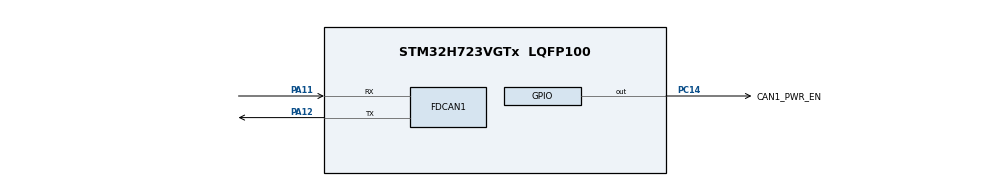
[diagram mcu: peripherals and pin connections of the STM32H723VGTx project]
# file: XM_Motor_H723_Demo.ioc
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FDCAN1.CalculateBaudRateNominal=1000000
FDCAN1.CalculateTimeBitNominal=1000
FDCAN1.CalculateTimeQuantumNominal=200.0
FDCAN1.NominalPrescaler=24
Mcu.Family=STM32H7
Mcu.Name=STM32H723VGTx
Mcu.Package=LQFP100
NVIC.FDCAN1_IT0_IRQn=true\:0\:0\:false\:false\:true\:true\:true\:true
NVIC.PriorityGroup=NVIC_PRIORITYGROUP_4
PA11.Mode=FDCAN_Activate
PA11.Signal=FDCAN1_RX
PA12.Mode=FDCAN_Activate
PA12.Signal=FDCAN1_TX
PC14-OSC32_IN.GPIO_Label=CAN1_PWR_EN
PC14-OSC32_IN.Signal=GPIO_Output
ProjectManager.HeapSize=0x200
ProjectManager.StackSize=0x400
ProjectManager.TargetToolchain=MDK-ARM V5.32
RCC.ADCFreq_Value=129000000
RCC.APB1Freq_Value=120000000
RCC.APB2Freq_Value=120000000
RCC.APB3Freq_Value=120000000
RCC.APB4Freq_Value=120000000
RCC.CortexFreq_Value=480000000
RCC.D1PPRE=RCC_APB3_DIV2
RCC.D2PPRE1=RCC_APB1_DIV2
RCC.D2PPRE2=RCC_APB2_DIV2
RCC.D3PPRE=RCC_APB4_DIV2
RCC.DIVM1=4
RCC.DIVN1=30
RCC.DIVP1=1
RCC.DIVQ1=4
RCC.HCLKFreq_Value=240000000
RCC.HPRE=RCC_HCLK_DIV2
RCC.PLL2FRACN=0
RCC.PLL3FRACN=0
RCC.PLLFRACN=0
RCC.SYSCLKFreq_VALUE=480000000
RCC.SYSCLKSource=RCC_SYSCLKSOURCE_PLLCLK
RCC.USBFreq_Value=120000000
VP_MEMORYMAP_VS_MEMORYMAP.Mode=CurAppReg
board=custom

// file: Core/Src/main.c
/* USER CODE BEGIN Header */
/**
  ******************************************************************************
  * @file           : main.c
  * @brief          : Main program body
  ******************************************************************************
  * @attention
  *
  * Copyright (c) 2024 STMicroelectronics.
  * All rights reserved.
  *
  * This software is licensed under terms that can be found in the LICENSE file
  * in the root directory of this software component.
  * If no LICENSE file comes with this software, it is provided AS-IS.
  *
  ******************************************************************************
  */
/* USER CODE END Header */
#include "main.h"
#include "fdcan.h"
#include "memorymap.h"
#include "gpio.h"

/* USER CODE BEGIN Includes */
#include "MI_motor_dev.h"
/* USER CODE END Includes */

void SystemClock_Config(void);

int main(void)
{

  /* MCU Configuration--------------------------------------------------------*/

  /* Reset of all peripherals, Initializes the Flash interface and the Systick. */
  HAL_Init();

  /* Configure the system clock */
  SystemClock_Config();

  /* Initialize all configured peripherals */
  MX_GPIO_Init();
  MX_FDCAN1_Init();
  /* USER CODE BEGIN 2 */
	HAL_GPIO_WritePin(CAN1_PWR_EN_GPIO_Port,CAN1_PWR_EN_Pin,1);
	MI_Motor_t hmotor;
	MI_motor_init(&hmotor,&hfdcan1);
	MI_motor_get_ID(&hmotor);
	MI_motor_enable(&hmotor,hmotor.EXT_ID.motor_id);
	MI_motor_controlmode(&hmotor, 0.05, 0,0,0,0);
	HAL_Delay(5000);
	MI_motor_stop(&hmotor);
  /* USER CODE END 2 */

  /* Infinite loop */
  while (1)
  {

  }
}

void SystemClock_Config(void)
{
  RCC_OscInitTypeDef RCC_OscInitStruct = {0};
  RCC_ClkInitTypeDef RCC_ClkInitStruct = {0};

  /** Supply configuration update enable
  */
  HAL_PWREx_ConfigSupply(PWR_LDO_SUPPLY);

  /** Configure the main internal regulator output voltage
  */
  __HAL_PWR_VOLTAGESCALING_CONFIG(PWR_REGULATOR_VOLTAGE_SCALE0);

  while(!__HAL_PWR_GET_FLAG(PWR_FLAG_VOSRDY)) {}

  /** Initializes the RCC Oscillators according to the specified parameters
  * in the RCC_OscInitTypeDef structure.
  */
  RCC_OscInitStruct.OscillatorType = RCC_OSCILLATORTYPE_HSI;
  RCC_OscInitStruct.HSIState = RCC_HSI_DIV1;
  RCC_OscInitStruct.HSICalibrationValue = 64;
  RCC_OscInitStruct.PLL.PLLState = RCC_PLL_ON;
  RCC_OscInitStruct.PLL.PLLSource = RCC_PLLSOURCE_HSI;
  RCC_OscInitStruct.PLL.PLLM = 4;
  RCC_OscInitStruct.PLL.PLLN = 30;
  RCC_OscInitStruct.PLL.PLLP = 1;
  RCC_OscInitStruct.PLL.PLLQ = 4;
  RCC_OscInitStruct.PLL.PLLR = 2;
  RCC_OscInitStruct.PLL.PLLRGE = RCC_PLL1VCIRANGE_3;
  RCC_OscInitStruct.PLL.PLLVCOSEL = RCC_PLL1VCOWIDE;
  RCC_OscInitStruct.PLL.PLLFRACN = 0;
  if (HAL_RCC_OscConfig(&RCC_OscInitStruct) != HAL_OK)
  {
    Error_Handler();
  }

  /** Initializes the CPU, AHB and APB buses clocks
  */
  RCC_ClkInitStruct.ClockType = RCC_CLOCKTYPE_HCLK|RCC_CLOCKTYPE_SYSCLK
                              |RCC_CLOCKTYPE_PCLK1|RCC_CLOCKTYPE_PCLK2
                              |RCC_CLOCKTYPE_D3PCLK1|RCC_CLOCKTYPE_D1PCLK1;
  RCC_ClkInitStruct.SYSCLKSource = RCC_SYSCLKSOURCE_PLLCLK;
  RCC_ClkInitStruct.SYSCLKDivider = RCC_SYSCLK_DIV1;
  RCC_ClkInitStruct.AHBCLKDivider = RCC_HCLK_DIV2;
  RCC_ClkInitStruct.APB3CLKDivider = RCC_APB3_DIV2;
  RCC_ClkInitStruct.APB1CLKDivider = RCC_APB1_DIV2;
  RCC_ClkInitStruct.APB2CLKDivider = RCC_APB2_DIV2;
  RCC_ClkInitStruct.APB4CLKDivider = RCC_APB4_DIV2;

  if (HAL_RCC_ClockConfig(&RCC_ClkInitStruct, FLASH_LATENCY_3) != HAL_OK)
  {
    Error_Handler();
  }
}

void Error_Handler(void)
{
  __disable_irq();
  while (1)
  {
  }
}
